# PIC32MZ1025DAL169 register map
Vendor: Microchip
Registers are 32-bit, read-write, reset 0x0 unless marked. A register's access mark holds for its fields unless they carry their own. Addresses are absolute, and some are shared; only a register's first bit layout is shown; [hi:lo] are bit positions; {n}, {i} and the like mark numbered series; 'fields as' and 'values as' point back to an identical list.

## DOS_EIP_00136_ssx
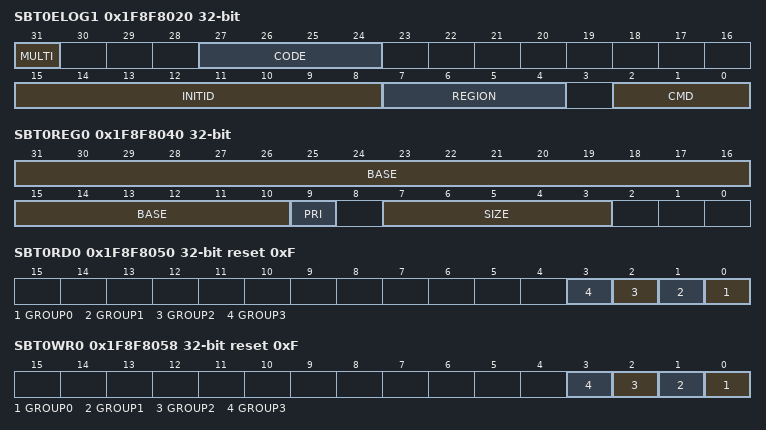
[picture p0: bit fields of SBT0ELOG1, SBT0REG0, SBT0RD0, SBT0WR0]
0x1F8F8020 SBT0ELOG1
  [31] MULTI, [27:24] CODE, [15:8] INITID ro, [7:4] REGION ro, [2:0] CMD ro
0x1F8F8024 SBT0ELOG2 ro
  [1:0] GROUP
0x1F8F8028 SBT0ECON
  [24] ERRP
0x1F8F8030 SBT0ECLRS ro
  [0] CLEAR
0x1F8F8038 SBT0ECLRM ro
  [0] CLEAR
0x1F8F8040 SBT0REG0 reset not defined — (power-on value 0000000000000000000000x-00000---)
  [31:10] BASE, [9] PRI ro, [7:3] SIZE
0x1F8F8050 SBT0RD0 reset 0xF
  [n] GROUP{n} (n=0..3)
0x1F8F8058 SBT0WR0 reset 0xF
  [n] GROUP{n} (n=0..3)
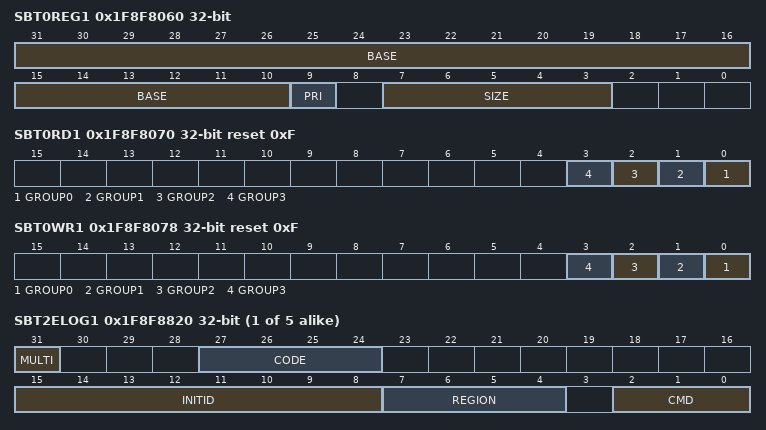
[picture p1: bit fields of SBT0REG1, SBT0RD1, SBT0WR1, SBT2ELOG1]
0x1F8F8060 SBT0REG1 reset not defined — (power-on value 0000000000000000000000x-00000---)
  [31:10] BASE, [9] PRI ro, [7:3] SIZE
0x1F8F8070 SBT0RD1 reset 0xF
  [n] GROUP{n} (n=0..3)
0x1F8F8078 SBT0WR1 reset 0xF
  [n] GROUP{n} (n=0..3)
{0x1F8F8020+0x400*i} SBT{i}ELOG1 (i=2..6)
  fields as SBT0ELOG1
{0x1F8F8024+0x400*i} SBT{i}ELOG2 ro (i=2..6)
  [1:0] GROUP
{0x1F8F8028+0x400*i} SBT{i}ECON (i=2..6)
  [24] ERRP
{0x1F8F8030+0x400*i} SBT{i}ECLRS ro (i=2..6)
  [0] CLEAR
{0x1F8F8038+0x400*i} SBT{i}ECLRM ro (i=2..6)
  [0] CLEAR
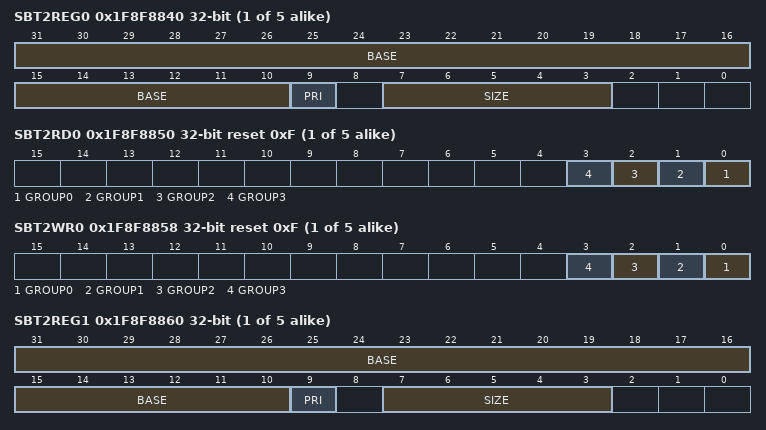
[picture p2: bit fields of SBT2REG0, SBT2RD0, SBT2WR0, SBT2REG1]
{0x1F8F8040+0x400*i} SBT{i}REG0 reset not defined (i=2..6) — (power-on value 0000000000000000000000x-00000---)
  [31:10] BASE, [9] PRI ro, [7:3] SIZE
{0x1F8F8050+0x400*i} SBT{i}RD0 reset 0xF (i=2..6)
  [n] GROUP{n} (n=0..3)
{0x1F8F8058+0x400*i} SBT{i}WR0 reset 0xF (i=2..6)
  [n] GROUP{n} (n=0..3)
{0x1F8F8060+0x400*i} SBT{i}REG1 reset not defined (i=2..6) — (power-on value 0000000000000000000000x-00000---)
  [31:10] BASE, [9] PRI ro, [7:3] SIZE
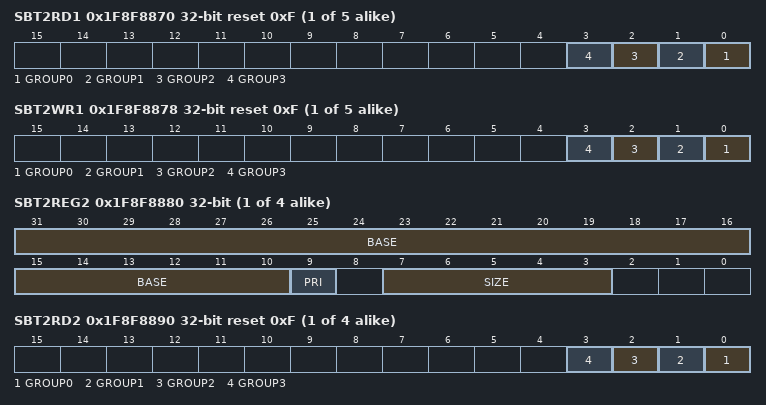
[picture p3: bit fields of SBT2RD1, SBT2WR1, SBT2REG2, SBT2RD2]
{0x1F8F8070+0x400*i} SBT{i}RD1 reset 0xF (i=2..6)
  [n] GROUP{n} (n=0..3)
{0x1F8F8078+0x400*i} SBT{i}WR1 reset 0xF (i=2..6)
  [n] GROUP{n} (n=0..3)
{0x1F8F8080+0x400*i} SBT{i}REG2 reset not defined (i=2..5) — (power-on value 0000000000000000000000x-00000---)
  [31:10] BASE, [9] PRI ro, [7:3] SIZE
{0x1F8F8090+0x400*i} SBT{i}RD2 reset 0xF (i=2..5)
  [n] GROUP{n} (n=0..3)
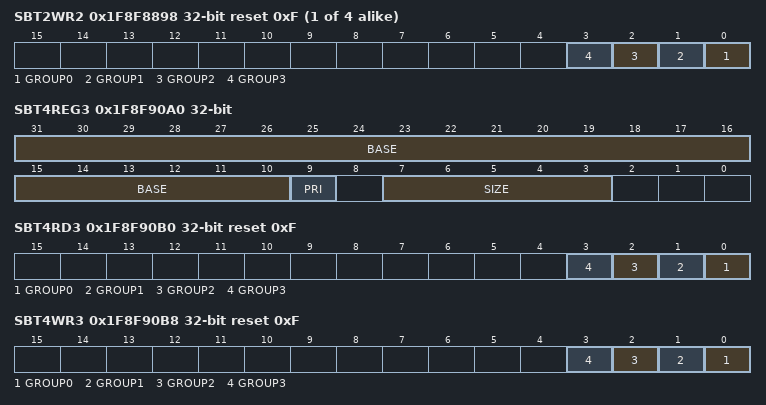
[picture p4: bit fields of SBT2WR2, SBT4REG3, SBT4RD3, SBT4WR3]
{0x1F8F8098+0x400*i} SBT{i}WR2 reset 0xF (i=2..5)
  [n] GROUP{n} (n=0..3)
0x1F8F90A0 SBT4REG3 reset not defined — (power-on value 0000000000000000000000x-00000---)
  [31:10] BASE, [9] PRI ro, [7:3] SIZE
0x1F8F90B0 SBT4RD3 reset 0xF
  [n] GROUP{n} (n=0..3)
0x1F8F90B8 SBT4WR3 reset 0xF
  [n] GROUP{n} (n=0..3)
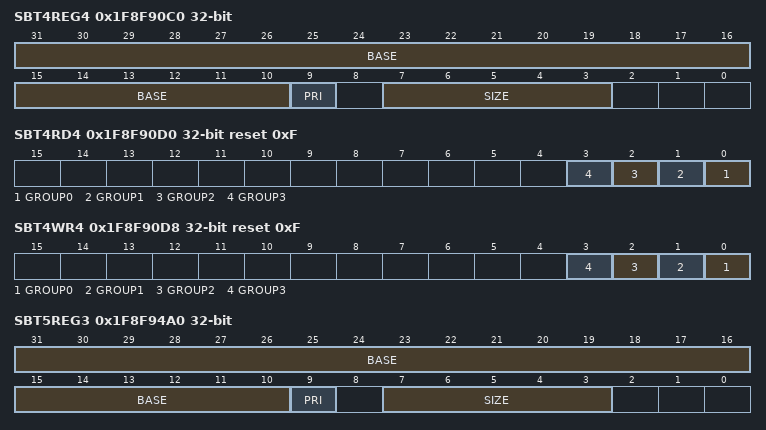
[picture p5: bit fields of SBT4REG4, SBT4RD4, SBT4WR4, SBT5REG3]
0x1F8F90C0 SBT4REG4 reset not defined — (power-on value 0000000000000000000000x-00000---)
  [31:10] BASE, [9] PRI ro, [7:3] SIZE
0x1F8F90D0 SBT4RD4 reset 0xF
  [n] GROUP{n} (n=0..3)
0x1F8F90D8 SBT4WR4 reset 0xF
  [n] GROUP{n} (n=0..3)
0x1F8F94A0 SBT5REG3 reset not defined — (power-on value 0000000000000000000000x-00000---)
  [31:10] BASE, [9] PRI ro, [7:3] SIZE
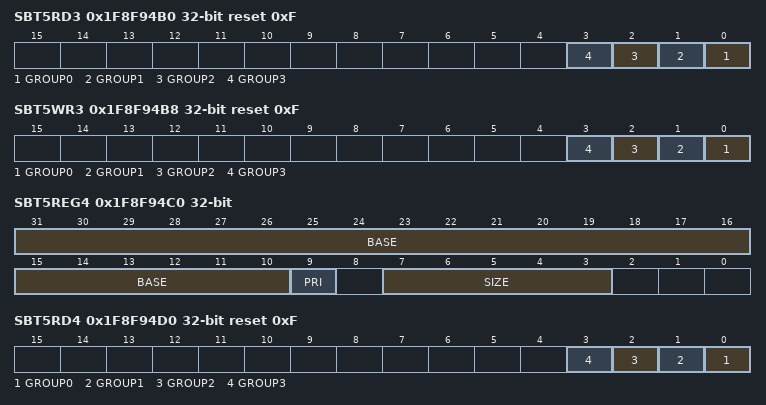
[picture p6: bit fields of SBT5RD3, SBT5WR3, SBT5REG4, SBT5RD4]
0x1F8F94B0 SBT5RD3 reset 0xF
  [n] GROUP{n} (n=0..3)
0x1F8F94B8 SBT5WR3 reset 0xF
  [n] GROUP{n} (n=0..3)
0x1F8F94C0 SBT5REG4 reset not defined — (power-on value 0000000000000000000000x-00000---)
  [31:10] BASE, [9] PRI ro, [7:3] SIZE
0x1F8F94D0 SBT5RD4 reset 0xF
  [n] GROUP{n} (n=0..3)
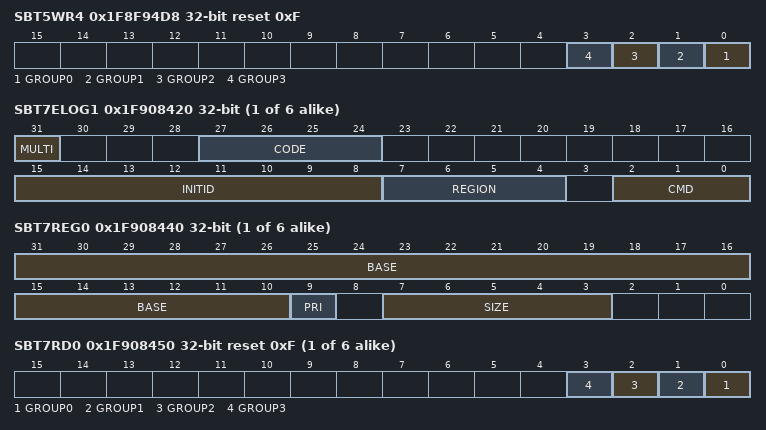
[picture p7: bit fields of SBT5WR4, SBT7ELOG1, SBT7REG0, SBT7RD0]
0x1F8F94D8 SBT5WR4 reset 0xF
  [n] GROUP{n} (n=0..3)
{0x1F906820+0x400*i} SBT{i}ELOG1 (i=7..12)
  fields as SBT0ELOG1
{0x1F906824+0x400*i} SBT{i}ELOG2 ro (i=7..12)
  [1:0] GROUP
{0x1F906828+0x400*i} SBT{i}ECON (i=7..12)
  [24] ERRP
{0x1F906830+0x400*i} SBT{i}ECLRS ro (i=7..12)
  [0] CLEAR
{0x1F906838+0x400*i} SBT{i}ECLRM ro (i=7..12)
  [0] CLEAR
{0x1F906840+0x400*i} SBT{i}REG0 reset not defined (i=7..12) — (power-on value 0000000000000000000000x-00000---)
  [31:10] BASE, [9] PRI ro, [7:3] SIZE
{0x1F906850+0x400*i} SBT{i}RD0 reset 0xF (i=7..12)
  [n] GROUP{n} (n=0..3)
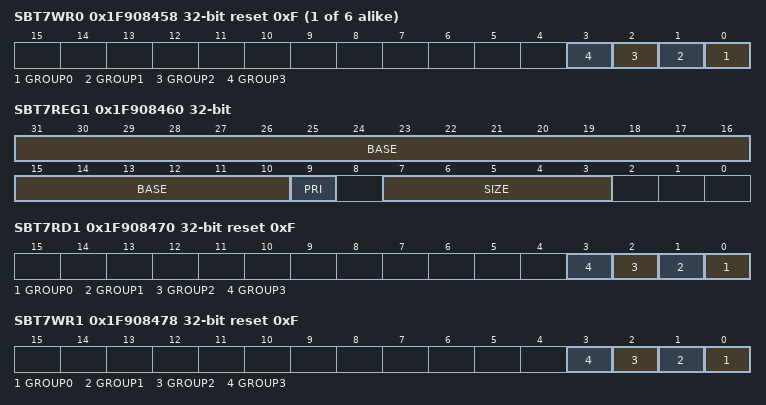
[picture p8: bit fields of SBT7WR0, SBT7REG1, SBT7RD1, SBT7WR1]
{0x1F906858+0x400*i} SBT{i}WR0 reset 0xF (i=7..12)
  [n] GROUP{n} (n=0..3)
0x1F908460 SBT7REG1 reset not defined — (power-on value 0000000000000000000000x-00000---)
  [31:10] BASE, [9] PRI ro, [7:3] SIZE
0x1F908470 SBT7RD1 reset 0xF
  [n] GROUP{n} (n=0..3)
0x1F908478 SBT7WR1 reset 0xF
  [n] GROUP{n} (n=0..3)
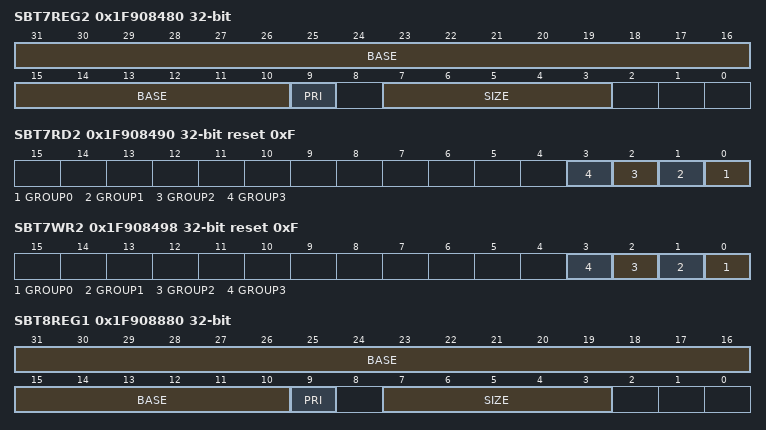
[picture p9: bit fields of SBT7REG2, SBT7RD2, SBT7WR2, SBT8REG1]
0x1F908480 SBT7REG2 reset not defined — (power-on value 0000000000000000000000x-00000---)
  [31:10] BASE, [9] PRI ro, [7:3] SIZE
0x1F908490 SBT7RD2 reset 0xF
  [n] GROUP{n} (n=0..3)
0x1F908498 SBT7WR2 reset 0xF
  [n] GROUP{n} (n=0..3)
0x1F908880 SBT8REG1 reset not defined — (power-on value 0000000000000000000000x-00000---)
  [31:10] BASE, [9] PRI ro, [7:3] SIZE
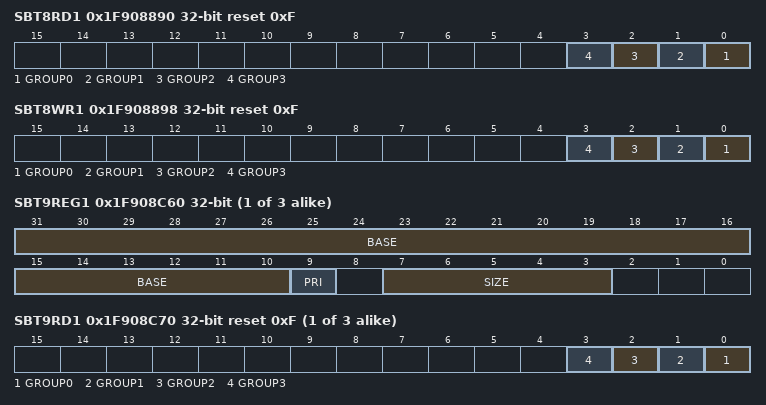
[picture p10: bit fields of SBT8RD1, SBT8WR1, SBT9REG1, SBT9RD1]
0x1F908890 SBT8RD1 reset 0xF
  [n] GROUP{n} (n=0..3)
0x1F908898 SBT8WR1 reset 0xF
  [n] GROUP{n} (n=0..3)
{0x1F906860+0x400*i} SBT{i}REG1 reset not defined (i=9..11) — (power-on value 0000000000000000000000x-00000---)
  [31:10] BASE, [9] PRI ro, [7:3] SIZE
{0x1F906870+0x400*i} SBT{i}RD1 reset 0xF (i=9..11)
  [n] GROUP{n} (n=0..3)
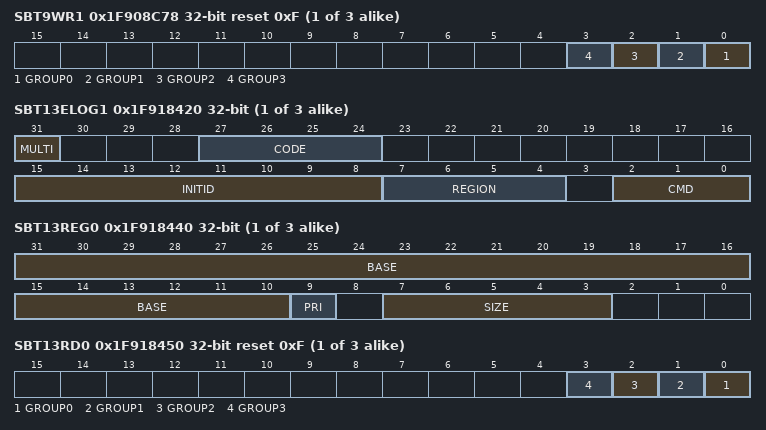
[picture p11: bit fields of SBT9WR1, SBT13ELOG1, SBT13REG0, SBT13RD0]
{0x1F906878+0x400*i} SBT{i}WR1 reset 0xF (i=9..11)
  [n] GROUP{n} (n=0..3)
{0x1F915020+0x400*i} SBT{i}ELOG1 (i=13..15)
  fields as SBT0ELOG1
{0x1F915024+0x400*i} SBT{i}ELOG2 ro (i=13..15)
  [1:0] GROUP
{0x1F915028+0x400*i} SBT{i}ECON (i=13..15)
  [24] ERRP
{0x1F915030+0x400*i} SBT{i}ECLRS ro (i=13..15)
  [0] CLEAR
{0x1F915038+0x400*i} SBT{i}ECLRM ro (i=13..15)
  [0] CLEAR
{0x1F915040+0x400*i} SBT{i}REG0 reset not defined (i=13..15) — (power-on value 0000000000000000000000x-00000---)
  [31:10] BASE, [9] PRI ro, [7:3] SIZE
{0x1F915050+0x400*i} SBT{i}RD0 reset 0xF (i=13..15)
  [n] GROUP{n} (n=0..3)
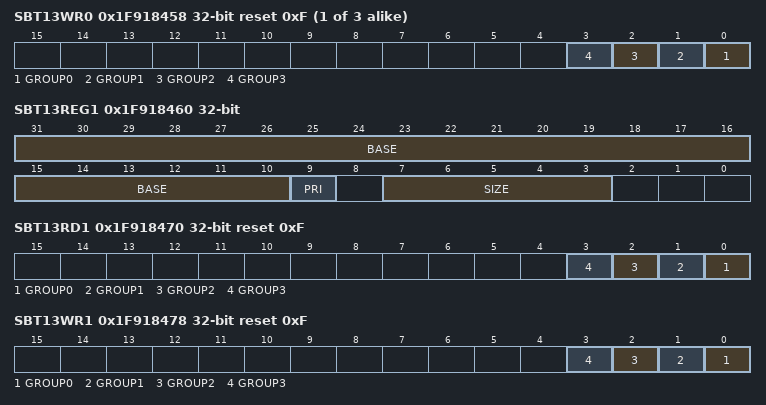
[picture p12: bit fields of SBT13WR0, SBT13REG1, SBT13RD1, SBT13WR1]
{0x1F915058+0x400*i} SBT{i}WR0 reset 0xF (i=13..15)
  [n] GROUP{n} (n=0..3)
0x1F918460 SBT13REG1 reset not defined — (power-on value 0000000000000000000000x-00000---)
  [31:10] BASE, [9] PRI ro, [7:3] SIZE
0x1F918470 SBT13RD1 reset 0xF
  [n] GROUP{n} (n=0..3)
0x1F918478 SBT13WR1 reset 0xF
  [n] GROUP{n} (n=0..3)
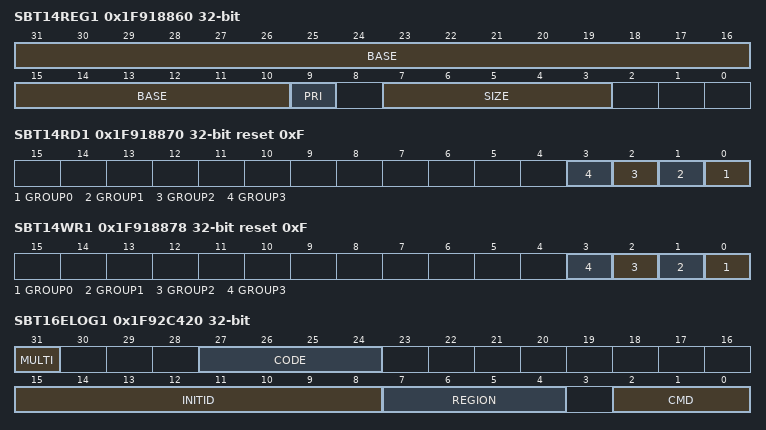
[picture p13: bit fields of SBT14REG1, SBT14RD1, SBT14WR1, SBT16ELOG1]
0x1F918860 SBT14REG1 reset not defined — (power-on value 0000000000000000000000x-00000---)
  [31:10] BASE, [9] PRI ro, [7:3] SIZE
0x1F918870 SBT14RD1 reset 0xF
  [n] GROUP{n} (n=0..3)
0x1F918878 SBT14WR1 reset 0xF
  [n] GROUP{n} (n=0..3)
0x1F92C420 SBT16ELOG1
  fields as SBT0ELOG1
0x1F92C424 SBT16ELOG2 ro
  [1:0] GROUP
0x1F92C428 SBT16ECON
  [24] ERRP
0x1F92C430 SBT16ECLRS ro
  [0] CLEAR
0x1F92C438 SBT16ECLRM ro
  [0] CLEAR
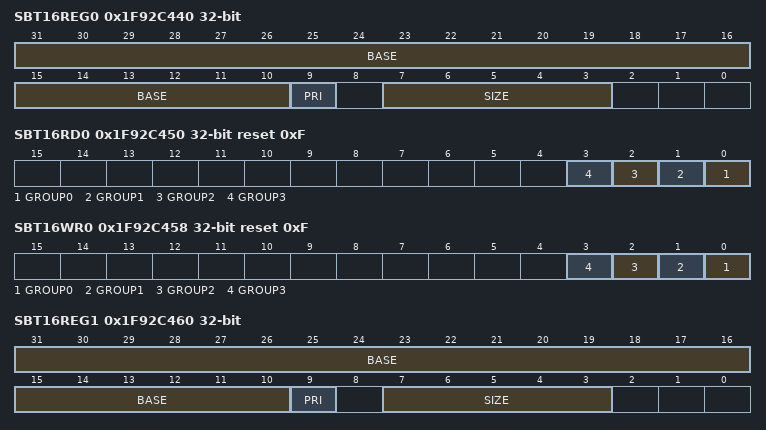
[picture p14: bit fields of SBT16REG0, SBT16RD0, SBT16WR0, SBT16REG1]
0x1F92C440 SBT16REG0 reset not defined — (power-on value 0000000000000000000000x-00000---)
  [31:10] BASE, [9] PRI ro, [7:3] SIZE
0x1F92C450 SBT16RD0 reset 0xF
  [n] GROUP{n} (n=0..3)
0x1F92C458 SBT16WR0 reset 0xF
  [n] GROUP{n} (n=0..3)
0x1F92C460 SBT16REG1 reset not defined — (power-on value 0000000000000000000000x-00000---)
  [31:10] BASE, [9] PRI ro, [7:3] SIZE
0x1F92C470 SBT16RD1 reset 0xF
  [n] GROUP{n} (n=0..3)
0x1F92C478 SBT16WR1 reset 0xF
  [n] GROUP{n} (n=0..3)
0x1F92C480 SBT16REG2 reset not defined — (power-on value 0000000000000000000000x-00000---)
  [31:10] BASE, [9] PRI ro, [7:3] SIZE
0x1F92C490 SBT16RD2 reset 0xF
  [n] GROUP{n} (n=0..3)
0x1F92C498 SBT16WR2 reset 0xF
  [n] GROUP{n} (n=0..3)
0x1F92C4A0 SBT16REG3 reset not defined — (power-on value 0000000000000000000000x-00000---)
  [31:10] BASE, [9] PRI ro, [7:3] SIZE
0x1F92C4B0 SBT16RD3 reset 0xF
  [n] GROUP{n} (n=0..3)
0x1F92C4B8 SBT16WR3 reset 0xF
  [n] GROUP{n} (n=0..3)
0x1F92C4C0 SBT16REG4 reset not defined — (power-on value 0000000000000000000000x-00000---)
  [31:10] BASE, [9] PRI ro, [7:3] SIZE
0x1F92C4D0 SBT16RD4 reset 0xF
  [n] GROUP{n} (n=0..3)
0x1F92C4D8 SBT16WR4 reset 0xF
  [n] GROUP{n} (n=0..3)
